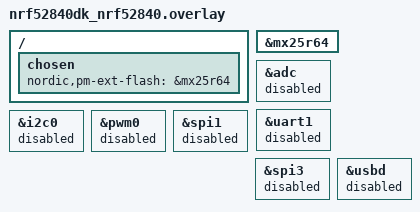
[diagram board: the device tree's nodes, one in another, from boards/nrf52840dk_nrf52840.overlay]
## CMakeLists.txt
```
#
# Copyright (c) 2023 Nordic Semiconductor ASA
#
# SPDX-License-Identifier: LicenseRef-Nordic-5-Clause
#

cmake_minimum_required(VERSION 3.20.0)

include(${CMAKE_CURRENT_LIST_DIR}/../../cmake/find_zephyr.cmake)

project(matter-thermostat)

# NORDIC SDK APP START

# Include all source files that are located in the Matter common directory.
include(${ZEPHYR_NCS_MATTER_MODULE_DIR}/cmake/sample.cmake)

ncs_get_zap_parent_dir(ZAP_PARENT_DIR)

target_include_directories(app PRIVATE
  src
  ${ZAP_PARENT_DIR}
)

target_sources(app PRIVATE
  src/app_task.cpp
  src/main.cpp
  src/temp_sensor_manager.cpp
  src/temperature_manager.cpp
  src/temperature_measurement/sensor.cpp
  src/zcl_callbacks.cpp
  ${ZEPHYR_NCS_MATTER_MODULE_DIR}/subsys/binding/binding_handler.cpp
)

ncs_configure_data_model()
# NORDIC SDK APP END
```

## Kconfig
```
#
# Copyright (c) 2023 Nordic Semiconductor
#
# SPDX-License-Identifier: LicenseRef-Nordic-5-Clause
#
mainmenu "Matter Thermostat sample application"

config THERMOSTAT_TEMPERATURE_STEP
	int "Defines a simulated temperature step. Use 0 for random"
	default 0
	help
	  A temperature step that defines differences between consecutive simulated temperature measurements. If set to 0, then the step is random.

config THERMOSTAT_SIMULATED_TEMPERATURE_MAX
	int "Maximum simulated temperature value"
	default 3000

config THERMOSTAT_SIMULATED_TEMPERATURE_MIN
	int "Minimum simulated temperature value"
	default 1500

config THERMOSTAT_SIMULATED_TEMPERATURE_CHANGE
	bool "Select to set the temperature to rise or fall"
	default y
	help
	  If set to true, the simulated temperature is rising. If set to false, the simulated temperature is falling.

# Enable Read Client functionality for all build configurations.
config CHIP_ENABLE_READ_CLIENT
	default y

# Sample configuration used for Thread networking
if OPENTHREAD

choice OPENTHREAD_NORDIC_LIBRARY_CONFIGURATION
	default OPENTHREAD_NORDIC_LIBRARY_MTD
endchoice

choice OPENTHREAD_DEVICE_TYPE
	default OPENTHREAD_MTD
endchoice

choice OPENTHREAD_IMPLEMENTATION
	default OPENTHREAD_SOURCES
endchoice

endif # OPENTHREAD

config CHIP_WIFI
	default y if SHIELD_NRF7002EB2

source "$(ZEPHYR_CONNECTEDHOMEIP_MODULE_DIR)/config/nrfconnect/chip-module/Kconfig.features"
source "$(ZEPHYR_CONNECTEDHOMEIP_MODULE_DIR)/config/nrfconnect/chip-module/Kconfig.defaults"
source "Kconfig.zephyr"
```

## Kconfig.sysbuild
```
#
# Copyright (c) 2023 Nordic Semiconductor ASA
#
# SPDX-License-Identifier: LicenseRef-Nordic-5-Clause
#

config MATTER_ADD_ON
	default y

#### Radio core selection
config NRF_DEFAULT_IPC_RADIO
	default y

# Enable IEEE802.15.4 serialization to network core
# This config automatically pulls in the `overlay-802154.conf` in the ipc_radio image
config NETCORE_IPC_RADIO_IEEE802154
	default y if SOC_SERIES_NRF53 && !WIFI_NRF70

# Enable Bluetooth serialization to network core
# This config automatically pulls in the `overlay-bt_hci_ipc.conf` in the ipc_radio image
config NETCORE_IPC_RADIO_BT_HCI_IPC
	default y if SOC_SERIES_NRF53

#### Matter OTA
config MATTER_ADD_ON_OTA
	default n if BOARD_NRF7120DK_NRF7120_CPUAPP

#### Bootloader
choice BOOTLOADER
	default BOOTLOADER_MCUBOOT if !BOARD_NRF7120DK_NRF7120_CPUAPP
endchoice

if BOOTLOADER_MCUBOOT

#### DFU multi-image support
config DFU_MULTI_IMAGE_PACKAGE_BUILD
	default y

config DFU_MULTI_IMAGE_PACKAGE_APP
	default y

#### DFU network core configuration
if SOC_SERIES_NRF53

choice MCUBOOT_MODE
	default MCUBOOT_MODE_OVERWRITE_ONLY
endchoice

choice BOOT_SIGNATURE_TYPE
	default BOOT_SIGNATURE_TYPE_RSA
endchoice

config SECURE_BOOT_NETCORE
	default y

config NETCORE_APP_UPDATE
	default y

config DFU_MULTI_IMAGE_PACKAGE_NET
	default y

endif # SOC_SERIES_NRF53
endif # BOOTLOADER_MCUBOOT

#### Enable generating factory data
config MATTER_ADD_ON_FACTORY_DATA_GENERATE
	default y

source "share/sysbuild/Kconfig"
```

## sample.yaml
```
sample:
  description: Matter Thermostat sample
  name: Matter Thermostat
common:
  tags:
    - sysbuild
    - ci_samples_matter
tests:
  sample.matter.thermostat.debug:
    sysbuild: true
    build_only: true
    integration_platforms:
      - nrf5340dk/nrf5340/cpuapp
      - nrf54lm20dk/nrf54lm20b/cpuapp
      - nrf54lm20dk/nrf54lm20a/cpuapp
    platform_allow:
      - nrf5340dk/nrf5340/cpuapp
      - nrf54l15dk/nrf54l15/cpuapp
      - nrf54lm20dk/nrf54lm20b/cpuapp
      - nrf54lm20dk/nrf54lm20a/cpuapp
  sample.matter.thermostat.nrf7002eb2.debug:
    sysbuild: true
    build_only: true
    extra_args:
      - thermostat_SHIELD=nrf7002eb2
      - SB_CONFIG_WIFI_NRF70=y
    integration_platforms:
      - nrf54lm20dk/nrf54lm20b/cpuapp
      - nrf54lm20dk/nrf54lm20a/cpuapp
    platform_allow:
      - nrf54lm20dk/nrf54lm20b/cpuapp
      - nrf54lm20dk/nrf54lm20a/cpuapp
  sample.matter.thermostat.nrf7120.debug:
    sysbuild: true
    build_only: true
    extra_args:
      - CONFIG_CHIP_WIFI=y
      - CONFIG_WIFI_NRF71_PATCH=y
      - EXTRA_DTC_OVERLAY_FILE=${ZEPHYR_NRFXLIB_MODULE_DIR}/nrf71_wifi/bins/0.1.0/nrf7120_wifi_patch.dtsi
    integration_platforms:
      - nrf7120dk/nrf7120/cpuapp
    platform_allow:
      - nrf7120dk/nrf7120/cpuapp
  sample.matter.thermostat.release:
    sysbuild: true
    build_only: true
    extra_args:
      - FILE_SUFFIX=release
    integration_platforms:
      - nrf54lm20dk/nrf54lm20b/cpuapp
      - nrf54lm20dk/nrf54lm20a/cpuapp
    platform_allow:
      - nrf5340dk/nrf5340/cpuapp
      - nrf54l15dk/nrf54l15/cpuapp
      - nrf54lm20dk/nrf54lm20b/cpuapp
      - nrf54lm20dk/nrf54lm20a/cpuapp
  sample.matter.thermostat.nrf7002eb2.release:
    sysbuild: true
    build_only: true
    extra_args:
      - FILE_SUFFIX=release
      - thermostat_SHIELD=nrf7002eb2
      - SB_CONFIG_WIFI_NRF70=y
    integration_platforms:
      - nrf54lm20dk/nrf54lm20b/cpuapp
      - nrf54lm20dk/nrf54lm20a/cpuapp
    platform_allow:
      - nrf54lm20dk/nrf54lm20b/cpuapp
      - nrf54lm20dk/nrf54lm20a/cpuapp
  sample.matter.thermostat.nrf7120.release:
    sysbuild: true
    build_only: true
    extra_args:
      - FILE_SUFFIX=release
      - CONFIG_CHIP_WIFI=y
      - CONFIG_WIFI_NRF71_PATCH=y
      - EXTRA_DTC_OVERLAY_FILE=${ZEPHYR_NRFXLIB_MODULE_DIR}/nrf71_wifi/bins/0.1.0/nrf7120_wifi_patch.dtsi
    integration_platforms:
      - nrf7120dk/nrf7120/cpuapp
    platform_allow:
      - nrf7120dk/nrf7120/cpuapp
  sample.matter.thermostat.tfm:
    sysbuild: true
    build_only: true
    extra_args:
      - FILE_SUFFIX=tfm
    integration_platforms:
      - nrf54l15dk/nrf54l15/cpuapp/ns
    platform_allow:
      - nrf54l15dk/nrf54l15/cpuapp/ns
```

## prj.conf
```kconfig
#
# Copyright (c) 2023 Nordic Semiconductor ASA
#
# SPDX-License-Identifier: LicenseRef-Nordic-5-Clause
#

# This sample uses Kconfig.defaults to set options common for all
# samples. This file should contain only options specific for this sample
# or overrides of default values.

# Enable CHIP
CONFIG_CHIP=y
CONFIG_CHIP_PROJECT_CONFIG="src/chip_project_config.h"
CONFIG_CHIP_DEVICE_PRODUCT_NAME="Matter Thermostat"

# Configure ZAP file name
CONFIG_MATTER_ZAP_FILE_PATH="${APPLICATION_CONFIG_DIR}/src/default_zap/thermostat.zap"

# 32782 == 0x800e (example thermostat product)
CONFIG_CHIP_DEVICE_PRODUCT_ID=32782
CONFIG_STD_CPP17=y

# Enable Matter pairing automatically on application start.
CONFIG_CHIP_ENABLE_PAIRING_AUTOSTART=y

# Enable Matter extended announcement and increase duration to 1 hour.
CONFIG_CHIP_BLE_EXT_ADVERTISING=y
CONFIG_CHIP_BLE_ADVERTISING_DURATION=60

# Add support for LEDs and buttons on Nordic development kits
CONFIG_DK_LIBRARY=y

# Bluetooth Low Energy configuration
CONFIG_BT_DEVICE_NAME="MatterThermo"

# Other settings
CONFIG_THREAD_NAME=y
CONFIG_MPU_STACK_GUARD=y
CONFIG_RESET_ON_FATAL_ERROR=n
CONFIG_CHIP_LIB_SHELL=y
CONFIG_MATTER_TEST_SHELL=y

# Disable NFC onboarding
CONFIG_CHIP_NFC_ONBOARDING_PAYLOAD=y

# Reduce application size
CONFIG_USE_SEGGER_RTT=n

# Enable Factory Data feature
CONFIG_CHIP_FACTORY_DATA=y
CONFIG_CHIP_FACTORY_DATA_BUILD=y
```

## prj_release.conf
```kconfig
#
# Copyright (c) 2023 Nordic Semiconductor ASA
#
# SPDX-License-Identifier: LicenseRef-Nordic-5-Clause
#

# This sample uses Kconfig.defaults to set options common for all
# samples. This file should contain only options specific for this sample
# or overrides of default values.

# Enable CHIP
CONFIG_CHIP=y
CONFIG_CHIP_PROJECT_CONFIG="src/chip_project_config.h"
CONFIG_CHIP_DEVICE_PRODUCT_NAME="Matter Thermostat"

# Configure ZAP file name
CONFIG_MATTER_ZAP_FILE_PATH="${APPLICATION_CONFIG_DIR}/src/default_zap/thermostat.zap"

# 32782 == 0x800e (example thermostat product)
CONFIG_CHIP_DEVICE_PRODUCT_ID=32782
CONFIG_STD_CPP17=y

# Enable Matter pairing automatically on application start.
CONFIG_CHIP_ENABLE_PAIRING_AUTOSTART=y

# Enable Matter extended announcement and increase duration to 1 hour.
CONFIG_CHIP_BLE_EXT_ADVERTISING=y
CONFIG_CHIP_BLE_ADVERTISING_DURATION=60

# Add support for LEDs and buttons on Nordic development kits
CONFIG_DK_LIBRARY=y

# Bluetooth Low Energy configuration
CONFIG_BT_DEVICE_NAME="MatterThermo"

# Enable system reset on fatal error
CONFIG_RESET_ON_FATAL_ERROR=y

# Disable all debug features
CONFIG_USE_SEGGER_RTT=n
CONFIG_SHELL=n
CONFIG_OPENTHREAD_SHELL=n
CONFIG_CONSOLE=n
CONFIG_UART_CONSOLE=n
CONFIG_SERIAL=n
CONFIG_LOG=n
CONFIG_LOG_MODE_MINIMAL=n
CONFIG_ASSERT_VERBOSE=n
CONFIG_ASSERT_NO_FILE_INFO=y
CONFIG_PRINTK=n
CONFIG_PRINTK_SYNC=n
CONFIG_THREAD_NAME=n

# Disable NFC onboarding
CONFIG_CHIP_NFC_ONBOARDING_PAYLOAD=n

# Enable Factory Data feature
CONFIG_CHIP_FACTORY_DATA=y
CONFIG_CHIP_FACTORY_DATA_BUILD=y

# Enable Watchdog
CONFIG_MATTER_WATCHDOG=y

# Enable LTO to decrease the flash usage.
CONFIG_LTO=y
CONFIG_ISR_TABLES_LOCAL_DECLARATION=y
```

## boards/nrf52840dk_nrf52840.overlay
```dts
/*
 * Copyright (c) 2023 Nordic Semiconductor ASA
 *
 * SPDX-License-Identifier: LicenseRef-Nordic-5-Clause
 */

#include <nrf52840_partitions.dtsi>

/ {
	chosen {
		nordic,pm-ext-flash = &mx25r64;
	};
};

&mx25r64 {
	status = "okay";
};

/* Disable unused peripherals to reduce power consumption */
&adc {
	status = "disabled";
};

&uart1 {
	status = "disabled";
};

&i2c0 {
	status = "disabled";
};

&pwm0 {
	status = "disabled";
};

&spi1 {
	status = "disabled";
};

&spi3 {
	status = "disabled";
};

&usbd {
	status = "disabled";
};
```

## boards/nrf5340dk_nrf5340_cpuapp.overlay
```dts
/*
 * Copyright (c) 2023 Nordic Semiconductor ASA
 *
 * SPDX-License-Identifier: LicenseRef-Nordic-5-Clause
 */

#include <nrf5340_cpuapp_partitions.dtsi>
#include <zephyr/dt-bindings/ipc_service/static_vrings.h>

/* Set IPC thread priority to the highest value to not collide with other threads. */
&ipc0 {
	zephyr,priority = <0 PRIO_COOP>;
};

/ {
	chosen {
		nordic,pm-ext-flash = &mx25r64;
	};
};

&mx25r64 {
	status = "okay";
};

/* Disable unused peripherals to reduce power consumption */
&adc {
	status = "disabled";
};

&i2c1 {
	status = "disabled";
};

&pwm0 {
	status = "disabled";
};

&spi2 {
	status = "disabled";
};

&usbd {
	status = "disabled";
};
```

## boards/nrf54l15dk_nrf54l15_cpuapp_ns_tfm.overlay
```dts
/*
 * Copyright (c) 2026 Nordic Semiconductor ASA
 *
 * SPDX-License-Identifier: LicenseRef-Nordic-5-Clause
 */

#include <nrf54l15_cpuapp_tfm_base_partitions.dtsi>
#include <nrf54l15_cpuapp_tfm_application_partitions.dtsi>

/ {
	aliases {
		/* Use watchdog wdt31 as the application watchdog */
		watchdog0 = &wdt31;
	};

	chosen {
		nordic,pm-ext-flash = &mx25r64;
	};
};

&mx25r64 {
	status = "okay";
};

&wdt31 {
	status = "okay";
};

/* Change IRQ ids to handle button interrupts.
 * The default values for nRF54L15 are 219 and 269,
 * but with TF-M they are reserved for the secure domain
 * (218 and 268 are reserved for the non-secure domain).
 */
&gpiote20 {
	interrupts = <218 NRF_DEFAULT_IRQ_PRIORITY>;
};

&gpiote30 {
	interrupts = <268 NRF_DEFAULT_IRQ_PRIORITY>;
};
```

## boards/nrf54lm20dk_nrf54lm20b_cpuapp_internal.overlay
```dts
/*
 * Copyright (c) 2026 Nordic Semiconductor ASA
 *
 * SPDX-License-Identifier: LicenseRef-Nordic-5-Clause
 */

#include <nrf54lm20_cpuapp_internal_partitions.dtsi>

/ {
	aliases {
		/* Use watchdog wdt31 as the application watchdog */
		watchdog0 = &wdt31;
	};
};

&wdt31 {
	status = "okay";
};
```

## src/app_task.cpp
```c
/*
 * Copyright (c) 2023 Nordic Semiconductor ASA
 *
 * SPDX-License-Identifier: LicenseRef-Nordic-5-Clause
 */

#include "app_task.h"

#include "temp_sensor_manager.h"
#include "temperature_manager.h"

#include "app/matter_init.h"
#include "app/task_executor.h"
#include "clusters/identify.h"

#include <app-common/zap-generated/attributes/Accessors.h>
#include <setup_payload/OnboardingCodesUtil.h>

#include <zephyr/logging/log.h>

LOG_MODULE_DECLARE(app, CONFIG_MATTER_LOG_LEVEL);

using namespace ::chip;
using namespace ::chip::app;
using namespace ::chip::DeviceLayer;

namespace
{
constexpr EndpointId kThermostatEndpointId = 1;

Nrf::Matter::IdentifyCluster sIdentifyCluster(kThermostatEndpointId);

#ifdef CONFIG_DK_LIBRARY
#define TEMPERATURE_BUTTON_MASK DK_BTN2_MSK
#endif
} /* namespace */

void AppTask::ButtonEventHandler(Nrf::ButtonState state, Nrf::ButtonMask hasChanged)
{
#ifdef CONFIG_DK_LIBRARY
	if (TEMPERATURE_BUTTON_MASK & hasChanged) {
		TemperatureButtonAction action = (TEMPERATURE_BUTTON_MASK & state) ? TemperatureButtonAction::Pushed :
										     TemperatureButtonAction::Released;
		Nrf::PostTask([action] { ThermostatHandler(action); });
	}
#endif
}

void AppTask::ThermostatHandler(const TemperatureButtonAction &action)
{
	if (action == TemperatureButtonAction::Pushed) {
		TemperatureManager::Instance().LogThermostatStatus();
	}
}

CHIP_ERROR AppTask::Init()
{
	/* Initialize Matter stack */
	ReturnErrorOnFailure(Nrf::Matter::PrepareServer(Nrf::Matter::InitData{ .mPostServerInitClbk = [] {
		CHIP_ERROR err = TempSensorManager::Instance().Init();
		if (err != CHIP_NO_ERROR) {
			LOG_ERR("TempSensorManager Init fail");
			return err;
		}
		err = TemperatureManager::Instance().Init();
		if (err != CHIP_NO_ERROR) {
			LOG_ERR("TemperatureManager Init fail");
		}
		return err;
	} }));

	if (!Nrf::GetBoard().Init(ButtonEventHandler)) {
		LOG_ERR("User interface initialization failed.");
		return CHIP_ERROR_INCORRECT_STATE;
	}

	/* Register Matter event handler that controls the connectivity status LED based on the captured Matter network
	 * state. */
	ReturnErrorOnFailure(Nrf::Matter::RegisterEventHandler(Nrf::Board::DefaultMatterEventHandler, 0));

	return Nrf::Matter::StartServer();
}

CHIP_ERROR AppTask::StartApp()
{
	ReturnErrorOnFailure(Init());

	while (true) {
		Nrf::DispatchNextTask();
	}

	return CHIP_NO_ERROR;
}
```

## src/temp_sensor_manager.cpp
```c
/*
 * Copyright (c) 2023 Nordic Semiconductor ASA
 *
 * SPDX-License-Identifier: LicenseRef-Nordic-5-Clause
 */

#include "temp_sensor_manager.h"
#include "app/task_executor.h"
#include "temperature_measurement/sensor.h"

#include <zephyr/logging/log.h>

LOG_MODULE_DECLARE(app, CONFIG_CHIP_APP_LOG_LEVEL);

using namespace chip;
using namespace chip::DeviceLayer;

static constexpr EndpointId kThermostatEndpoint = 1;

k_timer sSensorTimer;

CHIP_ERROR TempSensorManager::Init()
{
	k_timer_init(&sSensorTimer, &TempSensorManager::TimerEventHandler, nullptr);
	k_timer_start(&sSensorTimer, K_MSEC(kSensorTimerPeriodMs), K_MSEC(kSensorTimerPeriodMs));
	/* Workaround: Default null values are not correctly propagated from the zap file. Set it manually to make sure
	 * the starting value is cleared. */
	TempSensorManager::Instance().ClearLocalTemperature();
	TempSensorManager::Instance().ClearOutdoorTemperature();
	TemperatureSensor::Instance().FullMeasurement();

	return CHIP_NO_ERROR;
}

void TempSensorManager::TimerEventHandler(k_timer *timer)
{
	Nrf::PostTask([] { TempSensorManager::SensorTimerEventHandler(); });
}

/*
 *	This function is called when the timer is stopped and initiate temperature measurement.
 *	Depending ond object given to GetMeasurement() function thermostat will use true temperature device or simulated
 *	values
 */

void TempSensorManager::SensorTimerEventHandler()
{
	TemperatureSensor::Instance().FullMeasurement();
}

void TempSensorManager::SetLocalTemperature(int16_t temperature)
{
	PlatformMgr().LockChipStack();
	app::Clusters::Thermostat::Attributes::LocalTemperature::Set(kThermostatEndpoint, temperature);
	PlatformMgr().UnlockChipStack();
}

void TempSensorManager::ClearLocalTemperature()
{
	PlatformMgr().LockChipStack();
	app::Clusters::Thermostat::Attributes::LocalTemperature::SetNull(kThermostatEndpoint);
	PlatformMgr().UnlockChipStack();
}

void TempSensorManager::SetOutdoorTemperature(int16_t temperature)
{
	PlatformMgr().LockChipStack();
	app::Clusters::Thermostat::Attributes::OutdoorTemperature::Set(kThermostatEndpoint, temperature);
	PlatformMgr().UnlockChipStack();
}

void TempSensorManager::ClearOutdoorTemperature()
{
	PlatformMgr().LockChipStack();
	app::Clusters::Thermostat::Attributes::OutdoorTemperature::SetNull(kThermostatEndpoint);
	PlatformMgr().UnlockChipStack();
}
```
